# iomux_secure register map
Vendor: Texas Instruments
Registers are 32-bit, access per field, reset 0x0 unless marked. A register's access mark holds for its fields unless they carry their own. Offsets are as the file gives them; [hi:lo] are bit positions; {n}, {i} and the like mark numbered series.

## iomux_secure (part 2 of 2)
0x2D040 ctl_common_gpio15 — Port configuration register for IO GPIO15
  [4:0] IOSEL rw — Pinmux selection Control Mode can be used to select the IO functionality or drive 0/1/Hi-Z sel 5'd2 -- wifi_gpio_15 sel 5'd3 -- sdio_mmc_cmd sel 5'd4 -- spi1_miso sel 5'd5 -- uart1_rx sel 5'd6 -- uart0_cts sel 5'd9 -- gpt1_1 sel 5'd10 -- uart_rs232_rx sel 5'd11 -- jtag_tdi sel 5'd12 -- debug_bus_6 sel 5'd16 -- spi1_cs2 sel 5'd17 -- gpt0_pre_event sel 5'd18 -- gpt1_0_n sel 5'd19 -- sdio_d1 sel 5'd20 -- coex_req sel 5'd21 -- ble_rftrc sel 5'd22 -- ble_rfc_gpo_5 sel 5'd25 -- ble_rfc_gpi_3 sel 5'd26 -- swo_m3 sel 5'd27 -- swo_m33
    0=SEL_0 (reserved); 1=SEL_1 (reserved); 2=SEL_2 (wifi_gpio_15); 3=SEL_3 (sdio_mmc_cmd); 4=SEL_4 (spi1_miso); 5=SEL_5 (uart1_rx); 6=SEL_6 (uart0_cts); 7=SEL_7 (reserved); 8=SEL_8 (reserved); 9=SEL_9 (gpt1_1); 10=SEL_10 (uart_rs232_rx); 11=SEL_11 (jtag_tdi); 12=SEL_12 (debug_bus_6); 13=SEL_13 (reserved); 14=SEL_14 (reserved); 15=SEL_15 (reserved); 16=SEL_16 (spi1_cs2); 17=SEL_17 (gpt0_pre_event); 18=SEL_18 (gpt1_0_n); 19=SEL_19 (sdio_d1); 20=SEL_20 (coex_req); 21=SEL_21 (ble_rftrc); 22=SEL_22 (ble_rfc_gpo_5); 23=SEL_23 (reserved); 24=SEL_24 (reserved); 25=SEL_25 (ble_rfc_gpi_3); 26=SEL_26 (swo_m3); 27=SEL_27 (swo_m33); {v}=SEL_{v} (reserved) (v=28..31)
0x2D044 ctl_common_gpio16 — Port configuration register for IO GPIO16
  [4:0] IOSEL rw — Pinmux selection Control Mode can be used to select the IO functionality or drive 0/1/Hi-Z sel 5'd2 -- wifi_gpio_16 sel 5'd3 -- sdio_mmc_data_7 sel 5'd4 -- spi0_cs1 sel 5'd5 -- uart0_rts sel 5'd6 -- i2c1_data sel 5'd7 -- i2s_wclk sel 5'd8 -- pdm_bclk sel 5'd9 -- gpt0_0 sel 5'd10 -- uart_rs232_rx sel 5'd11 -- wake_observe_bus_12 sel 5'd12 -- debug_bus_5 sel 5'd16 -- spi1_cs2 sel 5'd18 -- gpt0_1_n sel 5'd19 -- sdio_d2 sel 5'd21 -- gpt1_0_n sel 5'd22 -- gpt_infrared sel 5'd23 -- ant_sel_0 sel 5'd26 -- trdata_0
    0=SEL_0 (reserved); 1=SEL_1 (reserved); 2=SEL_2 (wifi_gpio_16); 3=SEL_3 (sdio_mmc_data_7); 4=SEL_4 (spi0_cs1); 5=SEL_5 (uart0_rts); 6=SEL_6 (i2c1_data); 7=SEL_7 (i2s_wclk); 8=SEL_8 (pdm_bclk); 9=SEL_9 (gpt0_0); 10=SEL_10 (uart_rs232_rx); 11=SEL_11 (wake_observe_bus_12); 12=SEL_12 (debug_bus_5); 13=SEL_13 (reserved); 14=SEL_14 (reserved); 15=SEL_15 (reserved); 16=SEL_16 (spi1_cs2); 17=SEL_17 (reserved); 18=SEL_18 (gpt0_1_n); 19=SEL_19 (sdio_d2); 20=SEL_20 (reserved); 21=SEL_21 (gpt1_0_n); 22=SEL_22 (gpt_infrared); 23=SEL_23 (ant_sel_0); 24=SEL_24 (reserved); 25=SEL_25 (reserved); 26=SEL_26 (trdata_0); {v}=SEL_{v} (reserved) (v=27..31)
0x2D048 ctl_common_gpio17 — Port configuration register for IO GPIO17
  [4:0] IOSEL rw — Pinmux selection Control Mode can be used to select the IO functionality or drive 0/1/Hi-Z sel 5'd1 -- sdio_mmc_wp sel 5'd2 -- wifi_gpio_17 sel 5'd3 -- sdio_mmc_data_6 sel 5'd4 -- spi0_clk sel 5'd5 -- uart0_tx sel 5'd6 -- i2c0_clk sel 5'd7 -- i2s_data1 sel 5'd8 -- pdm_data0 sel 5'd9 -- gpt0_1 sel 5'd10 -- uart_rs232_tx sel 5'd11 -- wake_observe_bus_9 sel 5'd12 -- debug_bus_2 sel 5'd16 -- spi1_cs3 sel 5'd17 -- sdio_oob_irq sel 5'd18 -- gpt0_0_n sel 5'd20 -- coex_grant sel 5'd21 -- gpt1_1_n sel 5'd23 -- ant_sel_1 sel 5'd26 -- trdata_1
    0=SEL_0 (reserved); 1=SEL_1 (sdio_mmc_wp); 2=SEL_2 (wifi_gpio_17); 3=SEL_3 (sdio_mmc_data_6); 4=SEL_4 (spi0_clk); 5=SEL_5 (uart0_tx); 6=SEL_6 (i2c0_clk); 7=SEL_7 (i2s_data1); 8=SEL_8 (pdm_data0); 9=SEL_9 (gpt0_1); 10=SEL_10 (uart_rs232_tx); 11=SEL_11 (wake_observe_bus_9); 12=SEL_12 (debug_bus_2); 13=SEL_13 (reserved); 14=SEL_14 (reserved); 15=SEL_15 (reserved); 16=SEL_16 (spi1_cs3); 17=SEL_17 (sdio_oob_irq); 18=SEL_18 (gpt0_0_n); 19=SEL_19 (reserved); 20=SEL_20 (coex_grant); 21=SEL_21 (gpt1_1_n); 22=SEL_22 (reserved); 23=SEL_23 (ant_sel_1); 24=SEL_24 (reserved); 25=SEL_25 (reserved); 26=SEL_26 (trdata_1); {v}=SEL_{v} (reserved) (v=27..31)
0x2D04C ctl_common_gpio18 — Port configuration register for IO GPIO18
  [4:0] IOSEL rw — Pinmux selection Control Mode can be used to select the IO functionality or drive 0/1/Hi-Z sel 5'd2 -- wifi_gpio_18 sel 5'd3 -- sdio_mmc_data_5 sel 5'd4 -- spi0_miso sel 5'd5 -- uart0_rx sel 5'd6 -- i2c0_data sel 5'd7 -- i2s_data0 sel 5'd8 -- pdm_data1 sel 5'd9 -- gpt0_2 sel 5'd10 -- dcan_tx sel 5'd11 -- wake_observe_bus_10 sel 5'd12 -- debug_bus_3 sel 5'd16 -- spi1_cs4 sel 5'd17 -- sdio_oob_irq sel 5'd18 -- gpt0_0_n sel 5'd20 -- coex_req sel 5'd21 -- gpt1_2_n sel 5'd23 -- ant_sel_2 sel 5'd26 -- trdata_2
    0=SEL_0 (reserved); 1=SEL_1 (reserved); 2=SEL_2 (wifi_gpio_18); 3=SEL_3 (sdio_mmc_data_5); 4=SEL_4 (spi0_miso); 5=SEL_5 (uart0_rx); 6=SEL_6 (i2c0_data); 7=SEL_7 (i2s_data0); 8=SEL_8 (pdm_data1); 9=SEL_9 (gpt0_2); 10=SEL_10 (dcan_tx); 11=SEL_11 (wake_observe_bus_10); 12=SEL_12 (debug_bus_3); 13=SEL_13 (reserved); 14=SEL_14 (reserved); 15=SEL_15 (reserved); 16=SEL_16 (spi1_cs4); 17=SEL_17 (sdio_oob_irq); 18=SEL_18 (gpt0_0_n); 19=SEL_19 (reserved); 20=SEL_20 (coex_req); 21=SEL_21 (gpt1_2_n); 22=SEL_22 (reserved); 23=SEL_23 (ant_sel_2); 24=SEL_24 (reserved); 25=SEL_25 (reserved); 26=SEL_26 (trdata_2); {v}=SEL_{v} (reserved) (v=27..31)
0x2D050 ctl_common_gpio19 — Port configuration register for IO GPIO19
  [4:0] IOSEL rw — Pinmux selection Control Mode can be used to select the IO functionality or drive 0/1/Hi-Z sel 5'd2 -- wifi_gpio_19 sel 5'd3 -- sdio_mmc_data_4 sel 5'd4 -- spi0_mosi sel 5'd5 -- uart0_cts sel 5'd6 -- i2c1_clk sel 5'd7 -- i2s_bclk sel 5'd8 -- pdm_data0 sel 5'd9 -- gpt0_3 sel 5'd10 -- dcan_rx sel 5'd11 -- wake_observe_bus_11 sel 5'd12 -- debug_bus_4 sel 5'd16 -- gpt0_pre_event sel 5'd17 -- sdio_oob_irq sel 5'd18 -- gpt0_1_n sel 5'd19 -- sdio_d3 sel 5'd20 -- coex_priority sel 5'd21 -- gpt1_3_n sel 5'd22 -- gpt_infrared sel 5'd23 -- ant_sel_3 sel 5'd26 -- trdata_3
    0=SEL_0 (reserved); 1=SEL_1 (reserved); 2=SEL_2 (wifi_gpio_19); 3=SEL_3 (sdio_mmc_data_4); 4=SEL_4 (spi0_mosi); 5=SEL_5 (uart0_cts); 6=SEL_6 (i2c1_clk); 7=SEL_7 (i2s_bclk); 8=SEL_8 (pdm_data0); 9=SEL_9 (gpt0_3); 10=SEL_10 (dcan_rx); 11=SEL_11 (wake_observe_bus_11); 12=SEL_12 (debug_bus_4); 13=SEL_13 (reserved); 14=SEL_14 (reserved); 15=SEL_15 (reserved); 16=SEL_16 (gpt0_pre_event); 17=SEL_17 (sdio_oob_irq); 18=SEL_18 (gpt0_1_n); 19=SEL_19 (sdio_d3); 20=SEL_20 (coex_priority); 21=SEL_21 (gpt1_3_n); 22=SEL_22 (gpt_infrared); 23=SEL_23 (ant_sel_3); 24=SEL_24 (reserved); 25=SEL_25 (reserved); 26=SEL_26 (trdata_3); {v}=SEL_{v} (reserved) (v=27..31)
0x2D054 ctl_common_gpio20 — Port configuration register for IO GPIO20
  [4:0] IOSEL rw — Pinmux selection Control Mode can be used to select the IO functionality or drive 0/1/Hi-Z sel 5'd0 -- xspi_cs_flash sel 5'd2 -- wifi_gpio_20
    0=SEL_0 (xspi_cs_flash); 1=SEL_1 (reserved); 2=SEL_2 (wifi_gpio_20); {v}=SEL_{v} (reserved) (v=3..31)
{0x2D004+4i} ctl_common_gpio{i} (i=21..23) — Port configuration register for IO GPIO{i}
  [4:0] IOSEL rw — Pinmux selection Control Mode can be used to select the IO functionality or drive 0/1/Hi-Z sel 5'd0 -- xspi_data_{i-20} sel 5'd2 -- wifi_gpio_{i}
    0=SEL_0 (xspi_data_{i-20}); 1=SEL_1 (reserved); 2=SEL_2 (wifi_gpio_{i}); {v}=SEL_{v} (reserved) (v=3..31)
0x2D064 ctl_common_gpio24 — Port configuration register for IO GPIO24
  [4:0] IOSEL rw — Pinmux selection Control Mode can be used to select the IO functionality or drive 0/1/Hi-Z sel 5'd0 -- xspi_clk sel 5'd2 -- wifi_gpio_24
    0=SEL_0 (xspi_clk); 1=SEL_1 (reserved); 2=SEL_2 (wifi_gpio_24); {v}=SEL_{v} (reserved) (v=3..31)
0x2D068 ctl_common_gpio25 — Port configuration register for IO GPIO25
  [4:0] IOSEL rw — Pinmux selection Control Mode can be used to select the IO functionality or drive 0/1/Hi-Z sel 5'd0 -- xspi_data_0 sel 5'd2 -- wifi_gpio_25
    0=SEL_0 (xspi_data_0); 1=SEL_1 (reserved); 2=SEL_2 (wifi_gpio_25); {v}=SEL_{v} (reserved) (v=3..31)
0x2D06C ctl_common_gpio26 — Port configuration register for IO GPIO26
  [4:0] IOSEL rw — Pinmux selection Control Mode can be used to select the IO functionality or drive 0/1/Hi-Z sel 5'd1 -- xspi_data_4 sel 5'd2 -- wifi_gpio_26 sel 5'd4 -- spi0_cs1 sel 5'd5 -- uart0_rts sel 5'd6 -- i2c1_clk sel 5'd7 -- i2s_wclk sel 5'd8 -- pdm_bclk sel 5'd9 -- gpt0_0 sel 5'd10 -- dcan_tx sel 5'd11 -- wake_observe_bus_0 sel 5'd12 -- debug_bus_13 sel 5'd16 -- spi1_cs2 sel 5'd17 -- ext_clk sel 5'd18 -- gpt0_1_n sel 5'd19 -- gpt1_0_n sel 5'd20 -- coex_grant sel 5'd21 -- coex_req sel 5'd22 -- ble_rfc_gpo_4 sel 5'd23 -- ant_sel_0 sel 5'd24 -- gpt_infrared sel 5'd25 -- ble_rfc_gpi_1 sel 5'd26 -- ble_rfc_gpi_3 sel 5'd30 -- sdio_oob_irq
    0=SEL_0 (reserved); 1=SEL_1 (xspi_data_4); 2=SEL_2 (wifi_gpio_26); 3=SEL_3 (reserved); 4=SEL_4 (spi0_cs1); 5=SEL_5 (uart0_rts); 6=SEL_6 (i2c1_clk); 7=SEL_7 (i2s_wclk); 8=SEL_8 (pdm_bclk); 9=SEL_9 (gpt0_0); 10=SEL_10 (dcan_tx); 11=SEL_11 (wake_observe_bus_0); 12=SEL_12 (debug_bus_13); 13=SEL_13 (reserved); 14=SEL_14 (reserved); 15=SEL_15 (reserved); 16=SEL_16 (spi1_cs2); 17=SEL_17 (ext_clk); 18=SEL_18 (gpt0_1_n); 19=SEL_19 (gpt1_0_n); 20=SEL_20 (coex_grant); 21=SEL_21 (coex_req); 22=SEL_22 (ble_rfc_gpo_4); 23=SEL_23 (ant_sel_0); 24=SEL_24 (gpt_infrared); 25=SEL_25 (ble_rfc_gpi_1); 26=SEL_26 (ble_rfc_gpi_3); 27=SEL_27 (reserved); 28=SEL_28 (reserved); 29=SEL_29 (reserved); 30=SEL_30 (sdio_oob_irq); 31=SEL_31 (reserved)
0x2D070 ctl_common_gpio27 — Port configuration register for IO GPIO27
  [4:0] IOSEL rw — Pinmux selection Control Mode can be used to select the IO functionality or drive 0/1/Hi-Z sel 5'd1 -- xspi_data_5 sel 5'd2 -- wifi_gpio_27 sel 5'd4 -- spi0_clk sel 5'd5 -- uart0_tx sel 5'd6 -- i2c0_data sel 5'd7 -- i2s_data0 sel 5'd8 -- pdm_data0 sel 5'd9 -- gpt0_1 sel 5'd11 -- wake_observe_bus_1 sel 5'd12 -- debug_bus_14 sel 5'd16 -- spi1_cs3 sel 5'd18 -- gpt0_0_n sel 5'd19 -- gpt1_1_n sel 5'd20 -- coex_req sel 5'd22 -- ble_rfc_gpo_5 sel 5'd23 -- ant_sel_1 sel 5'd25 -- ble_rfc_gpi_2
    0=SEL_0 (reserved); 1=SEL_1 (xspi_data_5); 2=SEL_2 (wifi_gpio_27); 3=SEL_3 (reserved); 4=SEL_4 (spi0_clk); 5=SEL_5 (uart0_tx); 6=SEL_6 (i2c0_data); 7=SEL_7 (i2s_data0); 8=SEL_8 (pdm_data0); 9=SEL_9 (gpt0_1); 10=SEL_10 (reserved); 11=SEL_11 (wake_observe_bus_1); 12=SEL_12 (debug_bus_14); 13=SEL_13 (reserved); 14=SEL_14 (reserved); 15=SEL_15 (reserved); 16=SEL_16 (spi1_cs3); 17=SEL_17 (reserved); 18=SEL_18 (gpt0_0_n); 19=SEL_19 (gpt1_1_n); 20=SEL_20 (coex_req); 21=SEL_21 (reserved); 22=SEL_22 (ble_rfc_gpo_5); 23=SEL_23 (ant_sel_1); 24=SEL_24 (reserved); 25=SEL_25 (ble_rfc_gpi_2); {v}=SEL_{v} (reserved) (v=26..31)
0x2D074 ctl_common_gpio28 — Port configuration register for IO GPIO28
  [4:0] IOSEL rw — Pinmux selection Control Mode can be used to select the IO functionality or drive 0/1/Hi-Z sel 5'd1 -- xspi_data_6 sel 5'd2 -- wifi_gpio_28 sel 5'd4 -- spi0_miso sel 5'd5 -- uart0_rx sel 5'd6 -- i2c0_clk sel 5'd7 -- i2s_data1 sel 5'd8 -- pdm_bclk sel 5'd9 -- gpt0_2 sel 5'd11 -- wake_observe_bus_2 sel 5'd12 -- debug_bus_15 sel 5'd16 -- spi1_cs4 sel 5'd18 -- gpt0_0_n sel 5'd19 -- gpt1_2_n sel 5'd20 -- coex_priority sel 5'd22 -- ble_rfc_gpo_6 sel 5'd23 -- ant_sel_2 sel 5'd24 -- gpt0_pre_event sel 5'd25 -- ble_rfc_gpi_3
    0=SEL_0 (reserved); 1=SEL_1 (xspi_data_6); 2=SEL_2 (wifi_gpio_28); 3=SEL_3 (reserved); 4=SEL_4 (spi0_miso); 5=SEL_5 (uart0_rx); 6=SEL_6 (i2c0_clk); 7=SEL_7 (i2s_data1); 8=SEL_8 (pdm_bclk); 9=SEL_9 (gpt0_2); 10=SEL_10 (reserved); 11=SEL_11 (wake_observe_bus_2); 12=SEL_12 (debug_bus_15); 13=SEL_13 (reserved); 14=SEL_14 (reserved); 15=SEL_15 (reserved); 16=SEL_16 (spi1_cs4); 17=SEL_17 (reserved); 18=SEL_18 (gpt0_0_n); 19=SEL_19 (gpt1_2_n); 20=SEL_20 (coex_priority); 21=SEL_21 (reserved); 22=SEL_22 (ble_rfc_gpo_6); 23=SEL_23 (ant_sel_2); 24=SEL_24 (gpt0_pre_event); 25=SEL_25 (ble_rfc_gpi_3); {v}=SEL_{v} (reserved) (v=26..31)
0x2D078 ctl_common_gpio29 — Port configuration register for IO GPIO29
  [4:0] IOSEL rw — Pinmux selection Control Mode can be used to select the IO functionality or drive 0/1/Hi-Z sel 5'd1 -- xspi_data_7 sel 5'd2 -- wifi_gpio_29 sel 5'd4 -- spi0_mosi sel 5'd5 -- uart0_cts sel 5'd6 -- i2c1_data sel 5'd7 -- i2s_bclk sel 5'd8 -- pdm_data1 sel 5'd9 -- gpt0_3 sel 5'd10 -- dcan_rx sel 5'd11 -- wake_observe_bus_3 sel 5'd12 -- i2s_mclk sel 5'd16 -- spi1_cs4 sel 5'd17 -- ext_clk sel 5'd18 -- gpt0_1_n sel 5'd19 -- gpt1_3_n sel 5'd22 -- ble_rfc_gpo_7 sel 5'd23 -- ant_sel_3 sel 5'd30 -- sdio_oob_irq
    0=SEL_0 (reserved); 1=SEL_1 (xspi_data_7); 2=SEL_2 (wifi_gpio_29); 3=SEL_3 (reserved); 4=SEL_4 (spi0_mosi); 5=SEL_5 (uart0_cts); 6=SEL_6 (i2c1_data); 7=SEL_7 (i2s_bclk); 8=SEL_8 (pdm_data1); 9=SEL_9 (gpt0_3); 10=SEL_10 (dcan_rx); 11=SEL_11 (wake_observe_bus_3); 12=SEL_12 (i2s_mclk); 13=SEL_13 (reserved); 14=SEL_14 (reserved); 15=SEL_15 (reserved); 16=SEL_16 (spi1_cs4); 17=SEL_17 (ext_clk); 18=SEL_18 (gpt0_1_n); 19=SEL_19 (gpt1_3_n); 20=SEL_20 (reserved); 21=SEL_21 (reserved); 22=SEL_22 (ble_rfc_gpo_7); 23=SEL_23 (ant_sel_3); {v}=SEL_{v} (reserved) (v=24..29); 30=SEL_30 (sdio_oob_irq); 31=SEL_31 (reserved)
0x2D07C ctl_common_gpio30 — Port configuration register for IO GPIO30
  [4:0] IOSEL rw — Pinmux selection Control Mode can be used to select the IO functionality or drive 0/1/Hi-Z sel 5'd1 -- xspi_dqs sel 5'd2 -- wifi_gpio_30 sel 5'd3 -- xspi_reset_flash sel 5'd4 -- xspi_reset_ram sel 5'd5 -- i2c1_clk sel 5'd6 -- i2c0_clk sel 5'd7 -- i2s_data0 sel 5'd8 -- pdm_data0 sel 5'd9 -- gpt1_1 sel 5'd10 -- dcan_tx sel 5'd11 -- wake_observe_bus_4 sel 5'd12 -- xspi_cs_ram sel 5'd16 -- spi0_cs2 sel 5'd17 -- spi0_cs2 sel 5'd18 -- gpt0_2_n sel 5'd19 -- coex_grant sel 5'd20 -- coex_req sel 5'd21 -- ble_rftrc sel 5'd22 -- ble_rfc_gpo_4 sel 5'd23 -- ant_sel_0 sel 5'd24 -- cca sel 5'd25 -- ble_rfc_gpi_1 sel 5'd26 -- swo_m3 sel 5'd27 -- swo_m33 sel 5'd28 -- gpt1_pre_event sel 5'd29 -- gpt0_pre_event sel 5'd30 -- sdio_d3
    0=SEL_0 (reserved); 1=SEL_1 (xspi_dqs); 2=SEL_2 (wifi_gpio_30); 3=SEL_3 (xspi_reset_flash); 4=SEL_4 (xspi_reset_ram); 5=SEL_5 (i2c1_clk); 6=SEL_6 (i2c0_clk); 7=SEL_7 (i2s_data0); 8=SEL_8 (pdm_data0); 9=SEL_9 (gpt1_1); 10=SEL_10 (dcan_tx); 11=SEL_11 (wake_observe_bus_4); 12=SEL_12 (xspi_cs_ram); 13=SEL_13 (reserved); 14=SEL_14 (reserved); 15=SEL_15 (reserved); 16=SEL_16 (spi0_cs2); 17=SEL_17 (spi0_cs2); 18=SEL_18 (gpt0_2_n); 19=SEL_19 (coex_grant); 20=SEL_20 (coex_req); 21=SEL_21 (ble_rftrc); 22=SEL_22 (ble_rfc_gpo_4); 23=SEL_23 (ant_sel_0); 24=SEL_24 (cca); 25=SEL_25 (ble_rfc_gpi_1); 26=SEL_26 (swo_m3); 27=SEL_27 (swo_m33); 28=SEL_28 (gpt1_pre_event); 29=SEL_29 (gpt0_pre_event); 30=SEL_30 (sdio_d3); 31=SEL_31 (reserved)
0x2D080 ctl_common_gpio31 — Port configuration register for IO GPIO31
  [4:0] IOSEL rw — Pinmux selection Control Mode can be used to select the IO functionality or drive 0/1/Hi-Z sel 5'd1 -- xspi_cs_ram sel 5'd2 -- wifi_gpio_31 sel 5'd3 -- xspi_reset_flash sel 5'd4 -- spi1_cs1 sel 5'd5 -- uart1_rts sel 5'd6 -- i2c1_clk sel 5'd7 -- i2s_wclk sel 5'd8 -- pdm_bclk sel 5'd9 -- gpt1_0 sel 5'd10 -- dcan_tx sel 5'd16 -- spi0_cs3 sel 5'd17 -- ext_clk sel 5'd18 -- gpt1_1_n sel 5'd19 -- gpt0_0_n sel 5'd20 -- coex_grant sel 5'd22 -- ble_rfc_gpo_6 sel 5'd23 -- ant_sel_0 sel 5'd24 -- gpt_infrared sel 5'd25 -- ble_rfc_gpi_3 sel 5'd30 -- sdio_d2
    0=SEL_0 (reserved); 1=SEL_1 (xspi_cs_ram); 2=SEL_2 (wifi_gpio_31); 3=SEL_3 (xspi_reset_flash); 4=SEL_4 (spi1_cs1); 5=SEL_5 (uart1_rts); 6=SEL_6 (i2c1_clk); 7=SEL_7 (i2s_wclk); 8=SEL_8 (pdm_bclk); 9=SEL_9 (gpt1_0); 10=SEL_10 (dcan_tx); {v}=SEL_{v} (reserved) (v=11..15); 16=SEL_16 (spi0_cs3); 17=SEL_17 (ext_clk); 18=SEL_18 (gpt1_1_n); 19=SEL_19 (gpt0_0_n); 20=SEL_20 (coex_grant); 21=SEL_21 (reserved); 22=SEL_22 (ble_rfc_gpo_6); 23=SEL_23 (ant_sel_0); 24=SEL_24 (gpt_infrared); 25=SEL_25 (ble_rfc_gpi_3); {v}=SEL_{v} (reserved) (v=26..29); 30=SEL_30 (sdio_d2); 31=SEL_31 (reserved)
0x2D084 ctl_common_gpio32 — Port configuration register for IO GPIO32
  [4:0] IOSEL rw — Pinmux selection Control Mode can be used to select the IO functionality or drive 0/1/Hi-Z sel 5'd1 -- xspi_cs_ram sel 5'd2 -- wifi_gpio_32 sel 5'd3 -- spi1_cs1 sel 5'd4 -- spi1_clk sel 5'd5 -- uart1_tx sel 5'd6 -- i2c0_data sel 5'd7 -- i2s_data1 sel 5'd8 -- pdm_bclk sel 5'd9 -- gpt1_1 sel 5'd10 -- dcan_rx sel 5'd11 -- wake_observe_bus_5 sel 5'd16 -- spi0_cs3 sel 5'd18 -- gpt1_0_n sel 5'd19 -- gpt0_1_n sel 5'd20 -- coex_req sel 5'd23 -- ant_sel_1 sel 5'd30 -- sdio_d1
    0=SEL_0 (reserved); 1=SEL_1 (xspi_cs_ram); 2=SEL_2 (wifi_gpio_32); 3=SEL_3 (spi1_cs1); 4=SEL_4 (spi1_clk); 5=SEL_5 (uart1_tx); 6=SEL_6 (i2c0_data); 7=SEL_7 (i2s_data1); 8=SEL_8 (pdm_bclk); 9=SEL_9 (gpt1_1); 10=SEL_10 (dcan_rx); 11=SEL_11 (wake_observe_bus_5); {v}=SEL_{v} (reserved) (v=12..15); 16=SEL_16 (spi0_cs3); 17=SEL_17 (reserved); 18=SEL_18 (gpt1_0_n); 19=SEL_19 (gpt0_1_n); 20=SEL_20 (coex_req); 21=SEL_21 (reserved); 22=SEL_22 (reserved); 23=SEL_23 (ant_sel_1); {v}=SEL_{v} (reserved) (v=24..29); 30=SEL_30 (sdio_d1); 31=SEL_31 (reserved)
0x2D088 ctl_common_gpio33 — Port configuration register for IO GPIO33
  [4:0] IOSEL rw — Pinmux selection Control Mode can be used to select the IO functionality or drive 0/1/Hi-Z sel 5'd2 -- wifi_gpio_33 sel 5'd4 -- spi1_miso sel 5'd5 -- uart1_rx sel 5'd6 -- i2c0_clk sel 5'd7 -- i2s_data0 sel 5'd8 -- pdm_data0 sel 5'd9 -- gpt1_2 sel 5'd10 -- dcan_tx sel 5'd16 -- spi0_cs4 sel 5'd18 -- gpt1_0_n sel 5'd19 -- gpt0_2_n sel 5'd20 -- coex_grant sel 5'd23 -- ant_sel_2 sel 5'd24 -- gpt1_pre_event sel 5'd25 -- ble_rfc_gpi_2 sel 5'd30 -- sdio_d0
    0=SEL_0 (reserved); 1=SEL_1 (reserved); 2=SEL_2 (wifi_gpio_33); 3=SEL_3 (reserved); 4=SEL_4 (spi1_miso); 5=SEL_5 (uart1_rx); 6=SEL_6 (i2c0_clk); 7=SEL_7 (i2s_data0); 8=SEL_8 (pdm_data0); 9=SEL_9 (gpt1_2); 10=SEL_10 (dcan_tx); {v}=SEL_{v} (reserved) (v=11..15); 16=SEL_16 (spi0_cs4); 17=SEL_17 (reserved); 18=SEL_18 (gpt1_0_n); 19=SEL_19 (gpt0_2_n); 20=SEL_20 (coex_grant); 21=SEL_21 (reserved); 22=SEL_22 (reserved); 23=SEL_23 (ant_sel_2); 24=SEL_24 (gpt1_pre_event); 25=SEL_25 (ble_rfc_gpi_2); {v}=SEL_{v} (reserved) (v=26..29); 30=SEL_30 (sdio_d0); 31=SEL_31 (reserved)
0x2D08C ctl_common_gpio34 — Port configuration register for IO GPIO34
  [4:0] IOSEL rw — Pinmux selection Control Mode can be used to select the IO functionality or drive 0/1/Hi-Z sel 5'd1 -- xspi_reset_ram sel 5'd2 -- wifi_gpio_34 sel 5'd4 -- spi1_mosi sel 5'd5 -- uart1_cts sel 5'd6 -- i2c1_data sel 5'd7 -- i2s_bclk sel 5'd8 -- pdm_data1 sel 5'd9 -- gpt1_3 sel 5'd10 -- dcan_rx sel 5'd16 -- spi0_cs2 sel 5'd18 -- gpt1_1_n sel 5'd19 -- gpt0_3_n sel 5'd20 -- coex_req sel 5'd22 -- ble_rfc_gpo_7 sel 5'd23 -- ant_sel_3 sel 5'd25 -- ble_rfc_gpi_1 sel 5'd30 -- sdio_clk
    0=SEL_0 (reserved); 1=SEL_1 (xspi_reset_ram); 2=SEL_2 (wifi_gpio_34); 3=SEL_3 (reserved); 4=SEL_4 (spi1_mosi); 5=SEL_5 (uart1_cts); 6=SEL_6 (i2c1_data); 7=SEL_7 (i2s_bclk); 8=SEL_8 (pdm_data1); 9=SEL_9 (gpt1_3); 10=SEL_10 (dcan_rx); {v}=SEL_{v} (reserved) (v=11..15); 16=SEL_16 (spi0_cs2); 17=SEL_17 (reserved); 18=SEL_18 (gpt1_1_n); 19=SEL_19 (gpt0_3_n); 20=SEL_20 (coex_req); 21=SEL_21 (reserved); 22=SEL_22 (ble_rfc_gpo_7); 23=SEL_23 (ant_sel_3); 24=SEL_24 (reserved); 25=SEL_25 (ble_rfc_gpi_1); {v}=SEL_{v} (reserved) (v=26..29); 30=SEL_30 (sdio_clk); 31=SEL_31 (reserved)
0x2D090 ctl_common_gpio35 — Port configuration register for IO GPIO35
  [4:0] IOSEL rw — Pinmux selection Control Mode can be used to select the IO functionality or drive 0/1/Hi-Z sel 5'd1 -- xspi_reset_flash sel 5'd2 -- wifi_gpio_35 sel 5'd3 -- spi1_clk sel 5'd4 -- xspi_reset_ram sel 5'd5 -- uart1_rx sel 5'd6 -- i2c0_data sel 5'd7 -- i2s_data1 sel 5'd8 -- pdm_bclk sel 5'd9 -- gpt0_1 sel 5'd10 -- dcan_rx sel 5'd11 -- i2c1_data sel 5'd12 -- xspi_cs_ram sel 5'd16 -- spi0_cs4 sel 5'd17 -- spi0_cs3 sel 5'd18 -- gpt0_2_n sel 5'd19 -- gpt1_2_n sel 5'd20 -- coex_priority sel 5'd21 -- ble_rftrc sel 5'd22 -- ble_rfc_gpo_5 sel 5'd23 -- ant_sel_0 sel 5'd24 -- gpt1_pre_event sel 5'd25 -- ble_rfc_gpi_2 sel 5'd26 -- swo_m3 sel 5'd27 -- swo_m33 sel 5'd28 -- xspi_dqs sel 5'd29 -- coex_req sel 5'd30 -- sdio_cmd
    0=SEL_0 (reserved); 1=SEL_1 (xspi_reset_flash); 2=SEL_2 (wifi_gpio_35); 3=SEL_3 (spi1_clk); 4=SEL_4 (xspi_reset_ram); 5=SEL_5 (uart1_rx); 6=SEL_6 (i2c0_data); 7=SEL_7 (i2s_data1); 8=SEL_8 (pdm_bclk); 9=SEL_9 (gpt0_1); 10=SEL_10 (dcan_rx); 11=SEL_11 (i2c1_data); 12=SEL_12 (xspi_cs_ram); 13=SEL_13 (reserved); 14=SEL_14 (reserved); 15=SEL_15 (reserved); 16=SEL_16 (spi0_cs4); 17=SEL_17 (spi0_cs3); 18=SEL_18 (gpt0_2_n); 19=SEL_19 (gpt1_2_n); 20=SEL_20 (coex_priority); 21=SEL_21 (ble_rftrc); 22=SEL_22 (ble_rfc_gpo_5); 23=SEL_23 (ant_sel_0); 24=SEL_24 (gpt1_pre_event); 25=SEL_25 (ble_rfc_gpi_2); 26=SEL_26 (swo_m3); 27=SEL_27 (swo_m33); 28=SEL_28 (xspi_dqs); 29=SEL_29 (coex_req); 30=SEL_30 (sdio_cmd); 31=SEL_31 (reserved)
0x2D094 ctl_common_gpio36 — Port configuration register for IO GPIO36
  [4:0] IOSEL rw — Pinmux selection Control Mode can be used to select the IO functionality or drive 0/1/Hi-Z sel 5'd1 -- xspi_cs_ram sel 5'd2 -- wifi_gpio_36 sel 5'd3 -- sdio_mmc_pow2 sel 5'd4 -- sdio_mmc_wp sel 5'd11 -- wake_observe_bus_13 sel 5'd12 -- debug_bus_1 sel 5'd21 -- fast_clk_req sel 5'd22 -- ble_rfc_gpo_5 sel 5'd23 -- ant_sel_1 sel 5'd24 -- cca sel 5'd25 -- ble_rfc_gpi_2
    0=SEL_0 (reserved); 1=SEL_1 (xspi_cs_ram); 2=SEL_2 (wifi_gpio_36); 3=SEL_3 (sdio_mmc_pow2); 4=SEL_4 (sdio_mmc_wp); {v}=SEL_{v} (reserved) (v=5..10); 11=SEL_11 (wake_observe_bus_13); 12=SEL_12 (debug_bus_1); {v}=SEL_{v} (reserved) (v=13..20); 21=SEL_21 (fast_clk_req); 22=SEL_22 (ble_rfc_gpo_5); 23=SEL_23 (ant_sel_1); 24=SEL_24 (cca); 25=SEL_25 (ble_rfc_gpi_2); {v}=SEL_{v} (reserved) (v=26..31)
0x2D098 ctl_common_gpio37 — Port configuration register for IO GPIO37
  [4:0] IOSEL rw — Pinmux selection Control Mode can be used to select the IO functionality or drive 0/1/Hi-Z sel 5'd1 -- xspi_cs_ram sel 5'd2 -- wifi_gpio_37 sel 5'd3 -- sdio_mmc_pow1 sel 5'd4 -- sdio_mmc_wp sel 5'd11 -- wake_observe_bus_12 sel 5'd12 -- debug_bus_0 sel 5'd19 -- sdio_oob_irq sel 5'd20 -- coex_grant sel 5'd21 -- fast_clk_req sel 5'd22 -- ble_rfc_gpo_4 sel 5'd23 -- ant_sel_0 sel 5'd24 -- cca sel 5'd25 -- ble_rfc_gpi_1
    0=SEL_0 (reserved); 1=SEL_1 (xspi_cs_ram); 2=SEL_2 (wifi_gpio_37); 3=SEL_3 (sdio_mmc_pow1); 4=SEL_4 (sdio_mmc_wp); {v}=SEL_{v} (reserved) (v=5..10); 11=SEL_11 (wake_observe_bus_12); 12=SEL_12 (debug_bus_0); {v}=SEL_{v} (reserved) (v=13..18); 19=SEL_19 (sdio_oob_irq); 20=SEL_20 (coex_grant); 21=SEL_21 (fast_clk_req); 22=SEL_22 (ble_rfc_gpo_4); 23=SEL_23 (ant_sel_0); 24=SEL_24 (cca); 25=SEL_25 (ble_rfc_gpi_1); {v}=SEL_{v} (reserved) (v=26..31)
0x2D09C ctl_common_gpio38 — Port configuration register for IO GPIO38
  [4:0] IOSEL rw — Pinmux selection Control Mode can be used to select the IO functionality or drive 0/1/Hi-Z sel 5'd1 -- xspi_cs_ram sel 5'd2 -- wifi_gpio_38 sel 5'd3 -- ext_clk sel 5'd4 -- spi1_clk sel 5'd5 -- uart0_cts sel 5'd6 -- i2c1_clk sel 5'd7 -- i2s_bclk sel 5'd8 -- pdm_bclk sel 5'd9 -- gpt1_0 sel 5'd10 -- dcan_tx sel 5'd18 -- gpt1_1_n sel 5'd20 -- coex_grant sel 5'd23 -- ant_sel_0 sel 5'd29 -- coex_req
    0=SEL_0 (reserved); 1=SEL_1 (xspi_cs_ram); 2=SEL_2 (wifi_gpio_38); 3=SEL_3 (ext_clk); 4=SEL_4 (spi1_clk); 5=SEL_5 (uart0_cts); 6=SEL_6 (i2c1_clk); 7=SEL_7 (i2s_bclk); 8=SEL_8 (pdm_bclk); 9=SEL_9 (gpt1_0); 10=SEL_10 (dcan_tx); {v}=SEL_{v} (reserved) (v=11..17); 18=SEL_18 (gpt1_1_n); 19=SEL_19 (reserved); 20=SEL_20 (coex_grant); 21=SEL_21 (reserved); 22=SEL_22 (reserved); 23=SEL_23 (ant_sel_0); {v}=SEL_{v} (reserved) (v=24..28); 29=SEL_29 (coex_req); 30=SEL_30 (reserved); 31=SEL_31 (reserved)
0x2D0A0 ctl_common_gpio39 — Port configuration register for IO GPIO39
  [4:0] IOSEL rw — Pinmux selection Control Mode can be used to select the IO functionality or drive 0/1/Hi-Z sel 5'd1 -- xspi_reset_ram sel 5'd2 -- wifi_gpio_39 sel 5'd3 -- uart0_rx sel 5'd4 -- spi1_miso sel 5'd5 -- uart0_rts sel 5'd6 -- i2c1_data sel 5'd7 -- i2s_wclk sel 5'd8 -- pdm_data0 sel 5'd9 -- gpt1_1 sel 5'd10 -- dcan_rx sel 5'd11 -- xspi_dqs sel 5'd18 -- gpt1_0_n sel 5'd20 -- coex_req sel 5'd23 -- ant_sel_1 sel 5'd29 -- coex_priority
    0=SEL_0 (reserved); 1=SEL_1 (xspi_reset_ram); 2=SEL_2 (wifi_gpio_39); 3=SEL_3 (uart0_rx); 4=SEL_4 (spi1_miso); 5=SEL_5 (uart0_rts); 6=SEL_6 (i2c1_data); 7=SEL_7 (i2s_wclk); 8=SEL_8 (pdm_data0); 9=SEL_9 (gpt1_1); 10=SEL_10 (dcan_rx); 11=SEL_11 (xspi_dqs); {v}=SEL_{v} (reserved) (v=12..17); 18=SEL_18 (gpt1_0_n); 19=SEL_19 (reserved); 20=SEL_20 (coex_req); 21=SEL_21 (reserved); 22=SEL_22 (reserved); 23=SEL_23 (ant_sel_1); {v}=SEL_{v} (reserved) (v=24..28); 29=SEL_29 (coex_priority); 30=SEL_30 (reserved); 31=SEL_31 (reserved)
0x2D0A4 ctl_common_gpio40 — Port configuration register for IO GPIO40
  [4:0] IOSEL rw — Pinmux selection Control Mode can be used to select the IO functionality or drive 0/1/Hi-Z sel 5'd1 -- xspi_cs_ram sel 5'd2 -- wifi_gpio_40 sel 5'd4 -- spi1_mosi sel 5'd5 -- uart0_tx sel 5'd7 -- i2s_data0 sel 5'd8 -- pdm_data1 sel 5'd9 -- gpt1_2 sel 5'd16 -- gpt1_pre_event sel 5'd17 -- gpt0_pre_event sel 5'd18 -- gpt1_2_n sel 5'd20 -- coex_priority sel 5'd22 -- gpt_infrared sel 5'd23 -- ant_sel_2 sel 5'd29 -- coex_grant
    0=SEL_0 (reserved); 1=SEL_1 (xspi_cs_ram); 2=SEL_2 (wifi_gpio_40); 3=SEL_3 (reserved); 4=SEL_4 (spi1_mosi); 5=SEL_5 (uart0_tx); 6=SEL_6 (reserved); 7=SEL_7 (i2s_data0); 8=SEL_8 (pdm_data1); 9=SEL_9 (gpt1_2); {v}=SEL_{v} (reserved) (v=10..15); 16=SEL_16 (gpt1_pre_event); 17=SEL_17 (gpt0_pre_event); 18=SEL_18 (gpt1_2_n); 19=SEL_19 (reserved); 20=SEL_20 (coex_priority); 21=SEL_21 (reserved); 22=SEL_22 (gpt_infrared); 23=SEL_23 (ant_sel_2); {v}=SEL_{v} (reserved) (v=24..28); 29=SEL_29 (coex_grant); 30=SEL_30 (reserved); 31=SEL_31 (reserved)
0x2D0A8 ctl_common_gpio41 — Port configuration register for IO GPIO41
  [4:0] IOSEL rw — Pinmux selection Control Mode can be used to select the IO functionality or drive 0/1/Hi-Z sel 5'd1 -- xspi_cs_ram sel 5'd2 -- wifi_gpio_41 sel 5'd4 -- spi1_miso sel 5'd5 -- uart1_cts sel 5'd7 -- i2s_data0 sel 5'd9 -- gpt0_0 sel 5'd16 -- gpt1_pre_event sel 5'd17 -- gpt0_pre_event sel 5'd18 -- gpt0_1_n sel 5'd22 -- gpt_infrared sel 5'd23 -- ant_sel_0 sel 5'd29 -- coex_grant
    0=SEL_0 (reserved); 1=SEL_1 (xspi_cs_ram); 2=SEL_2 (wifi_gpio_41); 3=SEL_3 (reserved); 4=SEL_4 (spi1_miso); 5=SEL_5 (uart1_cts); 6=SEL_6 (reserved); 7=SEL_7 (i2s_data0); 8=SEL_8 (reserved); 9=SEL_9 (gpt0_0); {v}=SEL_{v} (reserved) (v=10..15); 16=SEL_16 (gpt1_pre_event); 17=SEL_17 (gpt0_pre_event); 18=SEL_18 (gpt0_1_n); 19=SEL_19 (reserved); 20=SEL_20 (reserved); 21=SEL_21 (reserved); 22=SEL_22 (gpt_infrared); 23=SEL_23 (ant_sel_0); {v}=SEL_{v} (reserved) (v=24..28); 29=SEL_29 (coex_grant); 30=SEL_30 (reserved); 31=SEL_31 (reserved)
0x2D0AC ctl_common_gpio42 — Port configuration register for IO GPIO42
  [4:0] IOSEL rw — Pinmux selection Control Mode can be used to select the IO functionality or drive 0/1/Hi-Z sel 5'd1 -- xspi_reset_ram sel 5'd2 -- wifi_gpio_42 sel 5'd3 -- uart1_rx sel 5'd4 -- spi1_mosi sel 5'd5 -- uart1_rts sel 5'd6 -- i2c0_data sel 5'd7 -- i2s_wclk sel 5'd8 -- pdm_data0 sel 5'd9 -- gpt0_1 sel 5'd10 -- dcan_rx sel 5'd11 -- xspi_dqs sel 5'd18 -- gpt0_0_n sel 5'd23 -- ant_sel_1 sel 5'd29 -- coex_req
    0=SEL_0 (reserved); 1=SEL_1 (xspi_reset_ram); 2=SEL_2 (wifi_gpio_42); 3=SEL_3 (uart1_rx); 4=SEL_4 (spi1_mosi); 5=SEL_5 (uart1_rts); 6=SEL_6 (i2c0_data); 7=SEL_7 (i2s_wclk); 8=SEL_8 (pdm_data0); 9=SEL_9 (gpt0_1); 10=SEL_10 (dcan_rx); 11=SEL_11 (xspi_dqs); {v}=SEL_{v} (reserved) (v=12..17); 18=SEL_18 (gpt0_0_n); {v}=SEL_{v} (reserved) (v=19..22); 23=SEL_23 (ant_sel_1); {v}=SEL_{v} (reserved) (v=24..28); 29=SEL_29 (coex_req); 30=SEL_30 (reserved); 31=SEL_31 (reserved)
0x2D0B0 ctl_common_gpio43 — Port configuration register for IO GPIO43
  [4:0] IOSEL rw — Pinmux selection Control Mode can be used to select the IO functionality or drive 0/1/Hi-Z sel 5'd1 -- xspi_cs_ram sel 5'd2 -- wifi_gpio_43 sel 5'd4 -- spi1_clk sel 5'd5 -- uart1_tx sel 5'd6 -- i2c0_clk sel 5'd7 -- i2s_bclk sel 5'd8 -- pdm_bclk sel 5'd9 -- gpt0_2 sel 5'd10 -- dcan_tx sel 5'd18 -- gpt0_2_n sel 5'd23 -- ant_sel_2 sel 5'd29 -- coex_priority
    0=SEL_0 (reserved); 1=SEL_1 (xspi_cs_ram); 2=SEL_2 (wifi_gpio_43); 3=SEL_3 (reserved); 4=SEL_4 (spi1_clk); 5=SEL_5 (uart1_tx); 6=SEL_6 (i2c0_clk); 7=SEL_7 (i2s_bclk); 8=SEL_8 (pdm_bclk); 9=SEL_9 (gpt0_2); 10=SEL_10 (dcan_tx); {v}=SEL_{v} (reserved) (v=11..17); 18=SEL_18 (gpt0_2_n); {v}=SEL_{v} (reserved) (v=19..22); 23=SEL_23 (ant_sel_2); {v}=SEL_{v} (reserved) (v=24..28); 29=SEL_29 (coex_priority); 30=SEL_30 (reserved); 31=SEL_31 (reserved)
0x2D0B4 ctl_common_gpio44 — Port configuration register for IO GPIO44
  [4:0] IOSEL rw — Pinmux selection Control Mode can be used to select the IO functionality or drive 0/1/Hi-Z sel 5'd0 -- xspi_clk_input sel 5'd2 -- wifi_gpio_44
    0=SEL_0 (xspi_clk_input); 1=SEL_1 (reserved); 2=SEL_2 (wifi_gpio_44); {v}=SEL_{v} (reserved) (v=3..31)
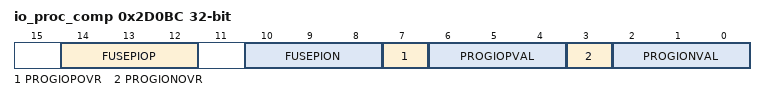
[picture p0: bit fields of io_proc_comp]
0x2D0BC io_proc_comp — The IO Process compensation is used to override the process compensation bits form the eFuse:IO Process: Common for all IOs.
  [14:12] FUSEPIOP ro — PROG IO P value from fuse ROM
  [10:8] FUSEPION ro — PROG IO N value from fuse ROM
  [7] PROGIOPOVR rw — The field selects the PROGIO P override between Fuse ROM and MMR
    0=DISABLE (Use Fuse ROM (bits (14:12))); 1=ENABLE (Use MMR (bits (6:4)))
  [6:4] PROGIOPVAL rw — This field configures the value of override PROG IO N
  [3] PROGIONOVR rw — The field selects the PROGIO N override between Fuse ROM and MMR
    0=DISABLE (Use Fuse ROM (bits (10:8))); 1=ENABLE (Use MMR (bits (2:0)))
  [2:0] PROGIONVAL rw — This field configures the value of override PROG IO N
